# f280015x_cmpss_lite_regs register map
Vendor: Texas Instruments
Peripheral module from a debugger description file (folder C2000).
Address unit: 16 bits
Registers are 16-bit, read-write, no defined reset value unless marked. A register's access mark holds for its fields unless they carry their own. Offsets are as the file gives them; lines under a group give offsets from that group; [hi:lo] are bit positions; {n}, {i} and the like mark numbered series; 'fields as' and 'values as' point back to an identical list; <NAME> marks a mode.

## CMPSS_LITE_REGS — CMPSS LITE Registers
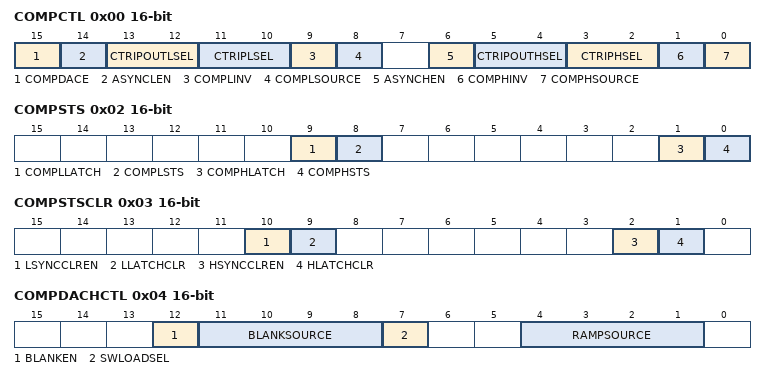
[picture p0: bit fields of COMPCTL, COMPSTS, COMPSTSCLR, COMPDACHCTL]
0x00 COMPCTL — CMPSS Comparator Control Register
  [15] COMPDACE — Comparator/DAC Enable
  [14] ASYNCLEN — Low Comparator Asynchronous Path Enable
  [13:12] CTRIPOUTLSEL — Low Comparator Trip Output Select
  [11:10] CTRIPLSEL — Low Comparator Trip Select
  [9] COMPLINV — Low Comparator Invert Select
  [8] COMPLSOURCE — Low Comparator Source Select
  [6] ASYNCHEN — High Comparator Asynchronous Path Enable
  [5:4] CTRIPOUTHSEL — High Comparator Trip Output Select
  [3:2] CTRIPHSEL — High Comparator Trip Select
  [1] COMPHINV — High Comparator Invert Select
  [0] COMPHSOURCE — High Comparator Source Select
0x01 COMPHYSCTL — CMPSS Comparator Hysteresis Control Register
  [3:0] COMPHYS — Comparator Hysteresis Trim
0x02 COMPSTS ro — CMPSS Comparator Status Register
  [9] COMPLLATCH — Low Comparator Latched Status
  [8] COMPLSTS — Low Comparator Status
  [1] COMPHLATCH — High Comparator Latched Status
  [0] COMPHSTS — High Comparator Status
0x03 COMPSTSCLR — CMPSS Comparator Status Clear Register
  [10] LSYNCCLREN — Low Comparator EPWMSYNCPER Clear Enable
  [9] LLATCHCLR — Low Comparator Latched Status Clear
  [2] HSYNCCLREN — High Comparator EPWMSYNCPER Clear Enable
  [1] HLATCHCLR — High Comparator Latched Status Clear
0x04 COMPDACHCTL — CMPSS High DAC Control Register
  [12] BLANKEN — EPWMBLANK Enable
  [11:8] BLANKSOURCE — EPWMBLANK Source Select
  [7] SWLOADSEL — Software Load Select
  [4:1] RAMPSOURCE — Ramp Generator Source Control
0x06 DACHVALS — CMPSS High DAC Value Shadow Register
  [11:0] DACVAL — DAC Value Control
0x07 DACHVALA ro — CMPSS High DAC Value Active Register
  [11:0] DACVAL — DAC Value Control
0x12 DACLVALS — CMPSS Low DAC Value Shadow Register
  [11:0] DACVAL — DAC Value Control
0x13 DACLVALA ro — CMPSS Low DAC Value Active Register
  [11:0] DACVAL — DAC Value Control
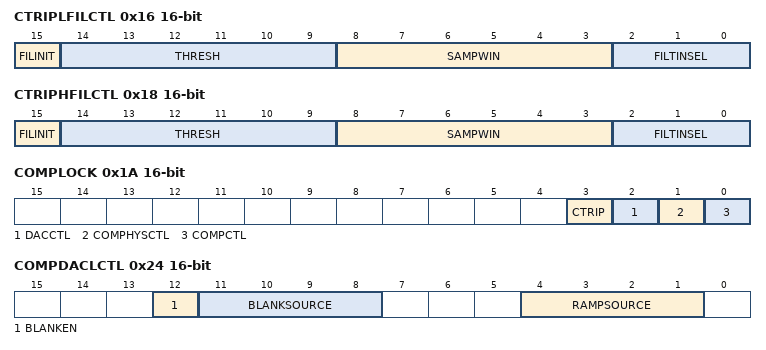
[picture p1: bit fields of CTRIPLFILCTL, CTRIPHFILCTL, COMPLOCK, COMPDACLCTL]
0x16 CTRIPLFILCTL — CTRIPL Filter Control Register
  [15] FILINIT — Filter Initialization Bit
  [14:9] THRESH — Majority Voting Threshold
  [8:3] SAMPWIN — Sample Window
  [2:0] FILTINSEL — Filter Input Select
0x17 CTRIPLFILCLKCTL — CTRIPL Filter Clock Control Register
  [15:0] CLKPRESCALE — Sample Clock Prescale
0x18 CTRIPHFILCTL — CTRIPH Filter Control Register
  fields as CTRIPLFILCTL
0x19 CTRIPHFILCLKCTL — CTRIPH Filter Clock Control Register
  [15:0] CLKPRESCALE — Sample Clock Prescale
0x1A COMPLOCK — CMPSS Lock Register
  [3] CTRIP — CTRIP Lock
  [2] DACCTL — DACCTL Lock
  [1] COMPHYSCTL — COMPHYSCTL Lock
  [0] COMPCTL — COMPCTL Lock
0x24 COMPDACLCTL — CMPSS Low DAC Control Register
  [12] BLANKEN — EPWMBLANK Enable
  [11:8] BLANKSOURCE — EPWMBLANK Source Select
  [4:1] RAMPSOURCE — Ramp Generator Source Control
0x37 CTRIPLFILCLKCTL2 — CTRIPL Filter Clock Control Register 2
  [7:0] CLKPRESCALEU — Sample Clock Prescale Upper Bits
0x39 CTRIPHFILCLKCTL2 — CTRIPH Filter Clock Control Register 2
  [7:0] CLKPRESCALEU — Sample Clock Prescale Upper Bits
